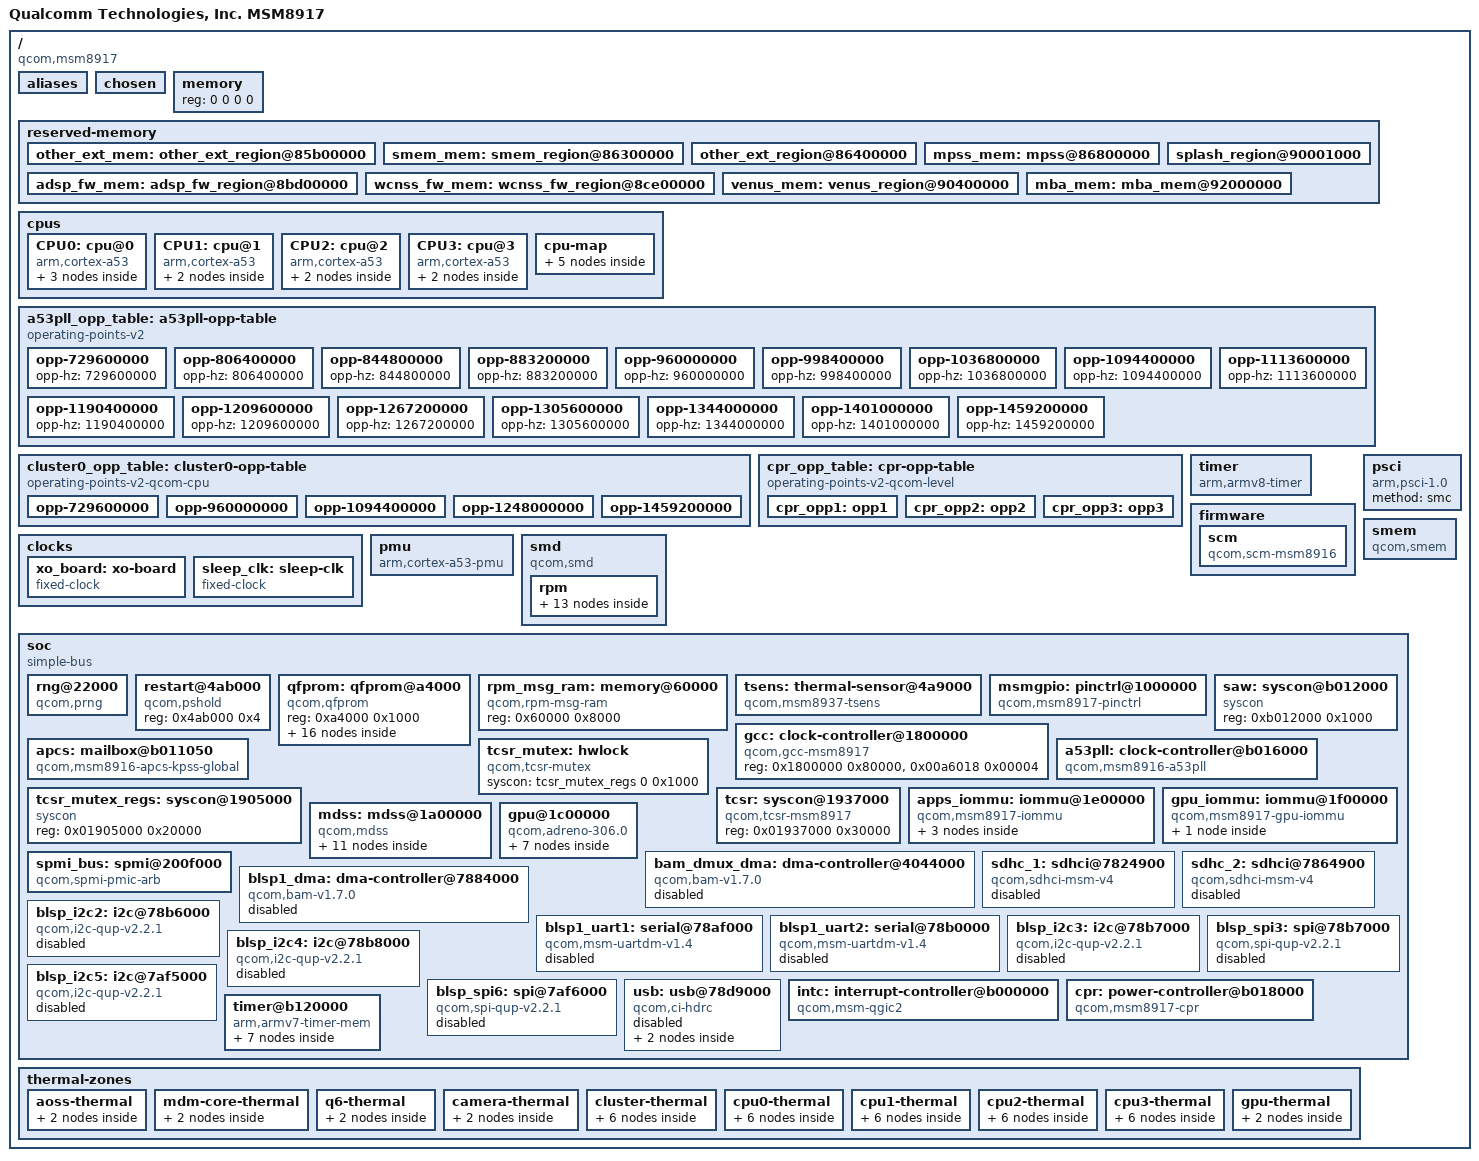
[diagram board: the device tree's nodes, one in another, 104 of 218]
// SPDX-License-Identifier: GPL-2.0-only

#include <dt-bindings/clock/qcom,gcc-msm8937.h>
#include <dt-bindings/clock/qcom,rpmcc.h>
#include <dt-bindings/interrupt-controller/arm-gic.h>
#include <dt-bindings/power/qcom-rpmpd.h>
#include <dt-bindings/thermal/thermal.h>

/ {
	model = "Qualcomm Technologies, Inc. MSM8917";
	compatible = "qcom,msm8917";
	qcom,msm-id = <303 0x0>, <308 0x0>, <309 0x0>;
	interrupt-parent = <&intc>;
	#address-cells = <2>;
	#size-cells = <2>;

	aliases {
		mmc0 = &sdhc_1; /* SDC1 eMMC slot */
		mmc1 = &sdhc_2; /* SDC2 SD card slot */
	};

	chosen { };

	memory {
		device_type = "memory";
		/* We expect the bootloader to fill in the reg */
		reg = <0 0 0 0>;
	};

	reserved-memory {
		#address-cells = <2>;
		#size-cells = <2>;
		ranges;

		other_ext_mem: other_ext_region@85b00000 {
			reg = <0x0 0x85b00000 0x0 0xd00000>;
			no-map;
		};

		smem_mem: smem_region@86300000 {
			reg = <0x0 0x86300000 0x0 0x100000>;
			no-map;
		};

		other_ext_region@86400000 {
			reg = <0x0 0x86400000 0x0 0x400000>;
			no-map;
		};

		mpss_mem: mpss@86800000 {
			reg = <0x0 0x86800000 0x0 0x5500000>;
			no-map;
		};

		adsp_fw_mem: adsp_fw_region@8bd00000 {
			reg = <0x0 0x8bd00000 0x0 0x1100000>;
			no-map;
		};

		wcnss_fw_mem: wcnss_fw_region@8ce00000 {
			reg = <0x0 0x8ce00000 0x0 0x700000>;
			no-map;
		};

		splash_region@90001000 {
			reg = <0x0 0x90000000 0x0 0x1400000>;
			no-map;
		};

		venus_mem: venus_region@90400000 {
			reg = <0x0 0x91400000 0x0 0x700000>;
			no-map;
		};

		mba_mem: mba_mem@92000000 {
			reg = <0x0 0x92000000 0x0 0x100000>;
			no-map;
		};
	};

	cpus {
		#address-cells = <1>;
		#size-cells = <0>;
		CPU0: cpu@0 {
			device_type = "cpu";
			compatible = "arm,cortex-a53";
			capacity-dmips-mhz = <1024>;
			reg = <0x100>;
			next-level-cache = <&L2_0>;
			enable-method = "psci";
			clocks = <&apcs>;
			#cooling-cells = <2>;
			operating-points-v2 = <&cluster0_opp_table>;
			power-domains = <&cpr>;
			power-domain-names = "cpr";
			l1-icache { compatible = "cache"; };
			l1-dcache { compatible = "cache"; };
			L2_0: l2-cache {
				compatible = "cache";
				cache-level = <2>;
			};
		};

		CPU1: cpu@1 {
			device_type = "cpu";
			compatible = "arm,cortex-a53";
			capacity-dmips-mhz = <1024>;
			reg = <0x101>;
			next-level-cache = <&L2_0>;
			enable-method = "psci";
			clocks = <&apcs>;
			#cooling-cells = <2>;
			operating-points-v2 = <&cluster0_opp_table>;
			power-domains = <&cpr>;
			power-domain-names = "cpr";
			l1-icache { compatible = "cache"; };
			l1-dcache { compatible = "cache"; };
		};

		CPU2: cpu@2 {
			device_type = "cpu";
			compatible = "arm,cortex-a53";
			capacity-dmips-mhz = <1024>;
			reg = <0x102>;
			next-level-cache = <&L2_0>;
			enable-method = "psci";
			clocks = <&apcs>;
			#cooling-cells = <2>;
			operating-points-v2 = <&cluster0_opp_table>;
			power-domains = <&cpr>;
			power-domain-names = "cpr";
			l1-icache { compatible = "cache"; };
			l1-dcache { compatible = "cache"; };
		};

		CPU3: cpu@3 {
			device_type = "cpu";
			compatible = "arm,cortex-a53";
			capacity-dmips-mhz = <1024>;
			reg = <0x103>;
			next-level-cache = <&L2_0>;
			enable-method = "psci";
			clocks = <&apcs>;
			#cooling-cells = <2>;
			operating-points-v2 = <&cluster0_opp_table>;
			power-domains = <&cpr>;
			power-domain-names = "cpr";
			l1-icache { compatible = "cache"; };
			l1-dcache { compatible = "cache"; };
		};

		cpu-map {
			cluster0 {
				core0 {
					cpu = <&CPU0>;
				};
				core1 {
					cpu = <&CPU1>;
				};
				core2 {
					cpu = <&CPU2>;
				};
				core3 {
					cpu = <&CPU3>;
				};
			};
		};
	};

	a53pll_opp_table: a53pll-opp-table {
		compatible = "operating-points-v2";
		opp-729600000 { opp-hz = /bits/ 64 <729600000>; };
		opp-806400000 { opp-hz = /bits/ 64 <806400000>; };
		opp-844800000 { opp-hz = /bits/ 64 <844800000>; };
		opp-883200000 { opp-hz = /bits/ 64 <883200000>; };
		opp-960000000 { opp-hz = /bits/ 64 <960000000>; };
		opp-998400000 { opp-hz = /bits/ 64 <998400000>; };
		opp-1036800000 { opp-hz = /bits/ 64 <1036800000>; };
		opp-1094400000 { opp-hz = /bits/ 64 <1094400000>; };
		opp-1113600000 { opp-hz = /bits/ 64 <1113600000>; };
		opp-1190400000 { opp-hz = /bits/ 64 <1190400000>; };
		opp-1209600000 { opp-hz = /bits/ 64 <1209600000>; };
		opp-1267200000 { opp-hz = /bits/ 64 <1267200000>; };
		opp-1305600000 { opp-hz = /bits/ 64 <1305600000>; };
		opp-1344000000 { opp-hz = /bits/ 64 <1344000000>; };
		opp-1401000000 { opp-hz = /bits/ 64 <1401000000>; };
		opp-1459200000 { opp-hz = /bits/ 64 <1459200000>; };
	};

	cluster0_opp_table: cluster0-opp-table {
		compatible = "operating-points-v2-qcom-cpu",
			     	 "operating-points-v2-kryo-cpu";
		nvmem-cells = <&cpr_efuse_speedbin>;
		opp-shared;
		opp-729600000 {
			opp-hz = /bits/ 64 <729600000>;
			required-opps = <&cpr_opp1>;
			opp-suspend;
		};
		opp-960000000 {
			opp-hz = /bits/ 64 <960000000>;
			required-opps = <&cpr_opp1>;
		};
		opp-1094400000 {
			opp-hz = /bits/ 64 <1094400000>;
			required-opps = <&cpr_opp2>;
		};
		opp-1248000000 {
			opp-hz = /bits/ 64 <1248000000>;
			required-opps = <&cpr_opp3>;
		};
		opp-1459200000 {
			opp-hz = /bits/ 64 <1459200000>;
			required-opps = <&cpr_opp3>;
		};
	};

	cpr_opp_table: cpr-opp-table {
		compatible = "operating-points-v2-qcom-level";
		cpr_opp1: opp1 {
			opp-level = <1>;
			qcom,opp-fuse-level = <1>;
		};
		cpr_opp2: opp2 {
			opp-level = <2>;
			qcom,opp-fuse-level = <2>;
		};
		cpr_opp3: opp3 {
			opp-level = <3>;
			qcom,opp-fuse-level = <3>;
		};
	};

	timer {
		compatible = "arm,armv8-timer";
		interrupts = <GIC_PPI 2 (GIC_CPU_MASK_SIMPLE(4) | IRQ_TYPE_LEVEL_LOW)>,
			     <GIC_PPI 3 (GIC_CPU_MASK_SIMPLE(4) | IRQ_TYPE_LEVEL_LOW)>,
			     <GIC_PPI 4 (GIC_CPU_MASK_SIMPLE(4) | IRQ_TYPE_LEVEL_LOW)>,
			     <GIC_PPI 1 (GIC_CPU_MASK_SIMPLE(4) | IRQ_TYPE_LEVEL_LOW)>;
		clock-frequency = <19200000>;
	};

	clocks {
		xo_board: xo-board {
			compatible = "fixed-clock";
			#clock-cells = <0>;
			clock-frequency = <19200000>;
			clock-output-names = "xo";
		};

		sleep_clk: sleep-clk {
			compatible = "fixed-clock";
			#clock-cells = <0>;
			clock-frequency = <32768>;
			clock-output-names = "sleep_clk";
		};
	};
    
	firmware {
		scm: scm {
			compatible = "qcom,scm-msm8916", "qcom,scm";
			clocks = <&gcc GCC_CRYPTO_CLK>,
				 <&gcc GCC_CRYPTO_AXI_CLK>,
				 <&gcc GCC_CRYPTO_AHB_CLK>;
			clock-names = "core", "bus", "iface";
			#reset-cells = <1>;
		};
	};

	pmu {
		compatible = "arm,cortex-a53-pmu";
		interrupts = <GIC_PPI 7 (GIC_CPU_MASK_SIMPLE(4) | IRQ_TYPE_LEVEL_HIGH)>;
	};

	psci {
		compatible = "arm,psci-1.0";
		method = "smc";
	};

	smd {
		compatible = "qcom,smd";

		rpm {
			interrupts = <GIC_SPI 168 IRQ_TYPE_EDGE_RISING>;
			qcom,ipc = <&apcs 8 0>;
			qcom,smd-edge = <15>;

			rpm_requests: rpm-requests {
				compatible = "qcom,rpm-msm8917";
				qcom,smd-channels = "rpm_requests";
				qcom,smd-force-open;

				rpmcc: clock-controller {
					compatible = "qcom,rpmcc-msm8917";
					#clock-cells = <1>;
				};

				rpmpd: power-controller {
					compatible = "qcom,msm8937-rpmpd";
					#power-domain-cells = <1>;
					operating-points-v2 = <&rpmpd_opp_table>;

					clocks = <&xo_board>;
					clock-names = "ref";
					rpmpd_opp_table: opp-table {
						compatible = "operating-points-v2";

						rpmpd_opp_ret: opp1 {
							opp-level = <16>;
						};

						rpmpd_opp_ret_plus: opp2 {
							opp-level = <32>;
						};

						rpmpd_opp_min_svs: opp3 {
							opp-level = <48>;
						};

						rpmpd_opp_low_svs: opp4 {
							opp-level = <64>;
						};

						rpmpd_opp_svs: opp5 {
							opp-level = <128>;
						};

						rpmpd_opp_svs_plus: opp6 {
							opp-level = <192>;
						};

						rpmpd_opp_nom: opp7 {
							opp-level = <256>;
						};

						rpmpd_opp_nom_plus: opp8 {
							opp-level = <320>;
						};

						rpmpd_opp_turbo: opp9 {
							opp-level = <384>;
						};
					};	
				};
			};
		};
	};

	smem {
		compatible = "qcom,smem";
		memory-region = <&smem_mem>;
		qcom,rpm-msg-ram = <&rpm_msg_ram>;
		hwlocks = <&tcsr_mutex 3>;
	};

	soc: soc {
		#address-cells = <1>;
		#size-cells = <1>;
		ranges = <0 0 0 0xffffffff>;
		compatible = "simple-bus";

		rng@22000 {
			compatible = "qcom,prng";
			reg = <0x00022000 0x200>;
			clocks = <&gcc GCC_PRNG_AHB_CLK>;
			clock-names = "core";
		};

		restart@4ab000 {
			compatible = "qcom,pshold";
			reg = <0x4ab000 0x4>;
		};

		qfprom: qfprom@a4000 {
			compatible = "qcom,qfprom";
			reg = <0xa4000 0x1000>;
			#address-cells = <1>;
			#size-cells = <1>;
			tsens_caldata: caldata@d0 {
				reg = <0x1d8 0x14>;
			};
			cpr_efuse_speedbin: speedbin@12c {
				reg = <0x12c 0x4>;
				bits = <2 3>;
			};
			cpr_efuse_init_voltage1: ivoltage1@21c {
				reg = <0x21c 0x4>;
				bits = <4 6>;
			};
			cpr_efuse_init_voltage2: ivoltage2@21a {
				reg = <0x21a 0x4>;
				bits = <2 6>;
			};
			cpr_efuse_init_voltage3: ivoltage3@218 {
				reg = <0x218 0x4>;
				bits = <0 6>;
			};
			cpr_efuse_quot_offset1: qoffset1@23b {
				reg = <0x23b 0x4>;
				bits = <2 6>;
			};
			cpr_efuse_quot_offset2: qoffset2@23a {
				reg = <0x23a 0x4>;
				bits = <4 6>;
			};
			cpr_efuse_quot_offset3: qoffset3@236 {
				reg = <0x236 0x4>;
				bits = <6 7>;
			};
			cpr_efuse_quot1: quot1@21d {
				reg = <0x21d 0x4>;
				bits = <2 12>;
			};
			cpr_efuse_quot2: quot2@21b {
				reg = <0x21b 0x4>;
				bits = <0 12>;
			};
			cpr_efuse_quot3: quot3@218 {
				reg = <0x218 0x4>;
				bits = <2 12>;
			};
			cpr_efuse_ring1: ring1@21f {
				reg = <0x21f 0x4>;
				bits = <4 3>;
			};
			cpr_efuse_ring2: ring2@21f {
				reg = <0x21f 0x4>;
				bits = <1 3>;
			};
			cpr_efuse_ring3: ring3@21e {
				reg = <0x21e 0x4>;
				bits = <6 3>;
			};
			cpr_efuse_revision: revision@22c {
				reg = <0x22c 0x4>;
				bits = <7 3>;
			};
			cpr_pvs_revision: revision@12d {
				reg = <0x12d 0x4>;
				bits = <0 3>;
			};
		};

		rpm_msg_ram: memory@60000 {
			compatible = "qcom,rpm-msg-ram";
			reg = <0x60000 0x8000>;
		};

		tsens: thermal-sensor@4a9000 {
			compatible = "qcom,msm8937-tsens", "qcom,tsens-v1";
			reg = <0x004a9000 0x1000>,
			      <0x004a8000 0x1000>;
			nvmem-cells = <&tsens_caldata>;
			nvmem-cell-names = "calib";
			#qcom,sensors = <10>;
			interrupts = <GIC_SPI 184 IRQ_TYPE_LEVEL_HIGH>;
			interrupt-names = "uplow";
			#thermal-sensor-cells = <1>;
		};

		msmgpio: pinctrl@1000000 {
			compatible = "qcom,msm8917-pinctrl";
			reg = <0x01000000 0x300000>;
			interrupts = <GIC_SPI 208 IRQ_TYPE_LEVEL_HIGH>;
			gpio-controller;
			gpio-ranges = <&msmgpio 0 0 134>;
			gpio-reserved-ranges = <0 4>, <20 4>;
			#gpio-cells = <2>;
			interrupt-controller;
			#interrupt-cells = <2>;
		};

		gcc: clock-controller@1800000 {
			compatible = "qcom,gcc-msm8917", "syscon";
			reg = <0x1800000 0x80000>,
			 <0x00a6018 0x00004>;
			reg-names = "cc_base", "gpu-bin";
			#clock-cells = <1>;
			#reset-cells = <1>;
			#power-domain-cells = <1>;
		};

		saw: syscon@b012000 {
			compatible = "syscon";
			reg = <0xb012000 0x1000>;
		};

		a53pll: clock-controller@b016000 {
			compatible = "qcom,msm8916-a53pll";
			reg = <0xb016000 0x34>;
			#clock-cells = <0>;
			clocks = <&xo_board>;
			clock-names = "xo";
			operating-points-v2 = <&a53pll_opp_table>;
		};

		apcs: mailbox@b011050 {
			compatible = "qcom,msm8916-apcs-kpss-global", "syscon";
			reg = <0xb011000 0x1000>;
			#mbox-cells = <1>;
			clocks = <&a53pll>, <&gcc GPLL0_EARLY>;
			clock-names = "pll", "aux";
			#clock-cells = <0>;
		};

		tcsr_mutex: hwlock {
			compatible = "qcom,tcsr-mutex";
			syscon = <&tcsr_mutex_regs 0 0x1000>;
			#hwlock-cells = <1>;
		};

		tcsr_mutex_regs: syscon@1905000 {
			compatible = "syscon";
			reg = <0x01905000 0x20000>;
		};

		tcsr: syscon@1937000 {
			compatible = "qcom,tcsr-msm8917", "syscon";
			reg = <0x01937000 0x30000>;
		};

		apps_iommu: iommu@1e00000 {
			#address-cells = <1>;
			#size-cells = <1>;
			#iommu-cells = <1>;
			compatible = "qcom,msm8917-iommu", "qcom,msm-iommu-v1";
			ranges  = <0 0x1e20000 0x20000>;
			clocks = <&gcc GCC_SMMU_CFG_CLK>,
				 <&gcc GCC_APSS_TCU_CLK>;
			clock-names = "iface", "bus";
			qcom,iommu-secure-id = <17>;

			iommu-ctx@14000 { // vfe
				compatible = "qcom,msm-iommu-v1-ns";
				reg = <0x14000 0x1000>;
				interrupts = <GIC_SPI 111 IRQ_TYPE_LEVEL_HIGH>;
			};

			iommu-ctx@15000 { // mdp_0
				compatible = "qcom,msm-iommu-v1-ns";
				reg = <0x15000 0x1000>;
				interrupts = <GIC_SPI 112 IRQ_TYPE_LEVEL_HIGH>;
			};

			iommu-ctx@16000 { // venus_ns
				compatible = "qcom,msm-iommu-v1-ns";
				reg = <0x16000 0x1000>;
				interrupts = <GIC_SPI 113 IRQ_TYPE_LEVEL_HIGH>;
			};
		};

		gpu_iommu: iommu@1f00000 {
			#address-cells = <1>;
			#size-cells = <1>;
			#iommu-cells = <1>;
			compatible = "qcom,msm8917-gpu-iommu", "qcom,msm-iommu-v1";
			ranges  = <0 0x1f08000 0x8000>;
			clocks = <&gcc GCC_SMMU_CFG_CLK>,
				 <&gcc GCC_GFX_TCU_CLK>;
			clock-names = "iface", "bus";
			qcom,iommu-secure-id = <18>;

			iommu-ctx@0000 { // gfx3d_user
				compatible = "qcom,msm-iommu-v1-ns";
				reg = <0x0000 0x1000>;
				interrupts = <GIC_SPI 241 IRQ_TYPE_LEVEL_HIGH>;
			};
		};

		mdss: mdss@1a00000 {
			compatible = "qcom,mdss";
			reg = <0x1a00000 0x1000>,
			      <0x1ab0000 0x1040>;
			reg-names = "mdss_phys", "vbif_phys";

			power-domains = <&gcc MDSS_GDSC>;

			clocks = <&gcc GCC_MDSS_AHB_CLK>,
				 <&gcc GCC_MDSS_AXI_CLK>,
				 <&gcc GCC_MDSS_VSYNC_CLK>;
			clock-names = "iface",
				      "bus",
				      "vsync";

			interrupts = <GIC_SPI 72 IRQ_TYPE_LEVEL_HIGH>;

			interrupt-controller;
			#interrupt-cells = <1>;

			#address-cells = <1>;
			#size-cells = <1>;
			ranges;

			dsi_phy0: dsi-phy@1a94400 {
				compatible = "qcom,dsi-phy-28nm-lp-single-fam-b";
				reg = <0x1a94a00 0xd4>,
				      <0x1a94400 0x280>,
				      <0x1a94b80 0x30>;
				reg-names = "dsi_pll",
					    "dsi_phy",
					    "dsi_phy_regulator";

				#clock-cells = <1>;
				#phy-cells = <0>;

				clocks = <&gcc GCC_MDSS_AHB_CLK>,
					 <&xo_board>;
				clock-names = "iface", "ref";
			};

			dsi0: dsi@1a94000 {
				compatible = "qcom,mdss-dsi-ctrl";
				reg = <0x1a94000 0x300>;
				reg-names = "dsi_ctrl";

				interrupt-parent = <&mdss>;
				interrupts = <4>;

				assigned-clocks = <&gcc BYTE0_CLK_SRC>,
						  <&gcc PCLK0_CLK_SRC>;
				assigned-clock-parents = <&dsi_phy0 0>,
							 <&dsi_phy0 1>;

				clocks = <&gcc GCC_MDSS_MDP_CLK>,
					 <&gcc GCC_MDSS_AHB_CLK>,
					 <&gcc GCC_MDSS_AXI_CLK>,
					 <&gcc GCC_MDSS_BYTE0_CLK>,
					 <&gcc GCC_MDSS_PCLK0_CLK>,
					 <&gcc GCC_MDSS_ESC0_CLK>;
				clock-names = "mdp_core",
					      "iface",
					      "bus",
					      "byte",
					      "pixel",
					      "core";
				phys = <&dsi_phy0>;
				phy-names = "dsi-phy";

				#address-cells = <1>;
				#size-cells = <0>;

				ports {
					#address-cells = <1>;
					#size-cells = <0>;

					port@0 {
						reg = <0>;
						dsi0_in: endpoint {
							remote-endpoint = <&mdp5_intf1_out>;
						};
					};

					port@1 {
						reg = <1>;
						dsi0_out: endpoint {
						};
					};
				};
			};

			mdp: mdp@1a01000 {
				compatible = "qcom,mdp5";
				reg = <0x01a01000 0x89000>;
				reg-names = "mdp_phys";

				interrupt-parent = <&mdss>;
				interrupts = <0>;

				clocks = <&gcc GCC_MDSS_AHB_CLK>,
					 <&gcc GCC_MDSS_AXI_CLK>,
					 <&gcc GCC_MDSS_MDP_CLK>,
					 <&gcc GCC_MDSS_VSYNC_CLK>;
				clock-names = "iface",
					      "bus",
					      "core",
					      "vsync";

				iommus = <&apps_iommu 0x15>;
				iommu-defer-attach;

				ports {
					#address-cells = <1>;
					#size-cells = <0>;

					port@0 {
						reg = <0>;
						mdp5_intf1_out: endpoint {
							remote-endpoint = <&dsi0_in>;
						};
					};
				};
			};
		};

		gpu@1c00000 {
			compatible = "qcom,adreno-306.0", "qcom,adreno";
			reg = <0x1c00000 0x20000>;
			reg-names = "kgsl_3d0_reg_memory";
			interrupts = <GIC_SPI 33 IRQ_TYPE_LEVEL_HIGH>;
			interrupt-names = "kgsl_3d0_irq";
			clocks = <&gcc GCC_OXILI_GFX3D_CLK>,
				 <&gcc GCC_OXILI_AHB_CLK>,
				 <&gcc GCC_BIMC_GFX_CLK>,
				 <&gcc GCC_BIMC_GPU_CLK>,
				 <&gcc GCC_GTCU_AHB_CLK>,
				 <&gcc GCC_GFX_TCU_CLK>,
				 <&gcc GCC_GFX_TBU_CLK>;
				 //<&rpmcc RPM_SMD_BIMC_GPU_CLK>;

			clock-names = "core", 
						  "iface", 
						  "mem_iface",
						  "alt_mem_iface", 
						  "gtcu_iface",
						  "gtcu", 
						  "gtbu";
						 // "bimc_gpu";
			power-domains = <&gcc OXILI_GX_GDSC>;
			operating-points-v2 = <&gpu_opp_table>;
			#cooling-cells = <2>;
			iommus = <&gpu_iommu 0>;

			gpu_opp_table: opp-table {
				compatible  ="operating-points-v2";
				opp-598000000 {
					opp-hz = /bits/ 64 <598000000>;
				};
				opp-523200000 {
					opp-hz = /bits/ 64 <523200000>;
				};
				opp-484800000 {
					opp-hz = /bits/ 64 <484800000>;
				};
				opp-400000000 {
					opp-hz = /bits/ 64 <400000000>;
				};
				opp-270000000 {
					opp-hz = /bits/ 64 <270000000>;
				};
				opp-19200000 {
					opp-hz = /bits/ 64 <19200000>;
				};
			};
		};

		spmi_bus: spmi@200f000 {
			compatible = "qcom,spmi-pmic-arb";
			reg = <0x0200f000 0x001000>,
			      <0x02400000 0x800000>,
			      <0x02c00000 0x800000>,
			      <0x03800000 0x200000>,
			      <0x0200a000 0x002100>;
			reg-names = "core", "chnls", "obsrvr", "intr", "cnfg";
			interrupt-names = "periph_irq";
			interrupts = <GIC_SPI 190 IRQ_TYPE_LEVEL_HIGH>;
			qcom,ee = <0>;
			qcom,channel = <0>;
			#address-cells = <2>;
			#size-cells = <0>;
			interrupt-controller;
			#interrupt-cells = <4>;
		};

		bam_dmux_dma: dma-controller@4044000 {
			compatible = "qcom,bam-v1.7.0";
			reg = <0x04044000 0x19000>;
			interrupts = <GIC_SPI 29 IRQ_TYPE_LEVEL_HIGH>;
			#dma-cells = <1>;
			qcom,ee = <0>;

			num-channels = <6>;
			qcom,num-ees = <1>;
			qcom,remote-power-collapse;

			status = "disabled";
		};

		sdhc_1: sdhci@7824900 {
			compatible = "qcom,sdhci-msm-v4";
			reg = <0x7824900 0x500>, <0x7824000 0x800>;
			reg-names = "hc_mem", "core_mem";

			interrupts = <GIC_SPI 123 IRQ_TYPE_LEVEL_HIGH>,
				     <GIC_SPI 138 IRQ_TYPE_LEVEL_HIGH>;
			interrupt-names = "hc_irq", "pwr_irq";
			clocks = <&gcc GCC_SDCC1_APPS_CLK>,
				 <&gcc GCC_SDCC1_AHB_CLK>,
				 <&xo_board>;
			clock-names = "core", "iface", "xo";
			mmc-hs200-1_8v;
			mmc-hs400-1_8v;
			mmc-ddr-1_8v;
			bus-width = <8>;
			non-removable;
			status = "disabled";
		};

		sdhc_2: sdhci@7864900 {
			compatible = "qcom,sdhci-msm-v4";
			reg = <0x7864900 0x500>, <0x7864000 0x800>;
			reg-names = "hc_mem", "core_mem";

			interrupts = <GIC_SPI 125 IRQ_TYPE_LEVEL_HIGH>,
				     <GIC_SPI 221 IRQ_TYPE_LEVEL_HIGH>;
			interrupt-names = "hc_irq", "pwr_irq";
			clocks = <&gcc GCC_SDCC2_APPS_CLK>,
				 <&gcc GCC_SDCC2_AHB_CLK>,
				 <&xo_board>;
			clock-names = "core", "iface", "xo";
			bus-width = <4>;
			status = "disabled";
		};

		blsp1_dma: dma-controller@7884000 {
			compatible = "qcom,bam-v1.7.0";
			reg = <0x07884000 0x1f000>;
			interrupts = <GIC_SPI 238 IRQ_TYPE_LEVEL_HIGH>;
			clocks = <&gcc GCC_BLSP1_AHB_CLK>;
			clock-names = "bam_clk";
			#dma-cells = <1>;
			qcom,ee = <0>;
			status = "disabled";
		};

		blsp1_uart1: serial@78af000 {
			compatible = "qcom,msm-uartdm-v1.4", "qcom,msm-uartdm";
			reg = <0x078af000 0x200>;
			interrupts = <GIC_SPI 107 IRQ_TYPE_LEVEL_HIGH>;
			clocks = <&gcc GCC_BLSP1_UART1_APPS_CLK>,
				<&gcc GCC_BLSP1_AHB_CLK>;
			clock-names = "core", "iface";
			dmas = <&blsp1_dma 1>, <&blsp1_dma 0>;
			dma-names = "rx", "tx";
			pinctrl-names = "default", "sleep";
			pinctrl-0 = <&blsp1_uart1_active>;
			pinctrl-1 = <&blsp1_uart1_sleep>;
			status = "disabled";
		};

		blsp1_uart2: serial@78b0000 {
			compatible = "qcom,msm-uartdm-v1.4", "qcom,msm-uartdm";
			reg = <0x078b0000 0x200>;
			interrupts = <GIC_SPI 108 IRQ_TYPE_LEVEL_HIGH>;
			clocks = <&gcc GCC_BLSP1_UART2_APPS_CLK>,
				<&gcc GCC_BLSP1_AHB_CLK>;
			clock-names = "core", "iface";
			dmas = <&blsp1_dma 3>, <&blsp1_dma 2>;
			dma-names = "rx", "tx";
			pinctrl-names = "default", "sleep";
			pinctrl-0 = <&blsp1_uart1_active>;
			pinctrl-1 = <&blsp1_uart1_sleep>;
			status = "disabled";
		};

		blsp_i2c2: i2c@78b6000 {
			compatible = "qcom,i2c-qup-v2.2.1";
			reg = <0x078b6000 0x600>;
			interrupts = <GIC_SPI 96 IRQ_TYPE_LEVEL_HIGH>;
			clocks = <&gcc GCC_BLSP1_AHB_CLK>,
				<&gcc GCC_BLSP1_QUP2_I2C_APPS_CLK>;
			clock-names = "iface", "core";
			pinctrl-names = "default", "sleep";
			pinctrl-0 = <&i2c_2_default>;
			pinctrl-1 = <&i2c_2_sleep>;
			#address-cells = <1>;
			#size-cells = <0>;
			status = "disabled";
		};

		blsp_i2c3: i2c@78b7000 {
			compatible = "qcom,i2c-qup-v2.2.1";
			reg = <0x078b7000 0x600>;
			interrupts = <GIC_SPI 97 IRQ_TYPE_LEVEL_HIGH>;
			clocks = <&gcc GCC_BLSP1_AHB_CLK>,
				 <&gcc GCC_BLSP1_QUP3_I2C_APPS_CLK>;
			clock-names = "iface", "core";
			pinctrl-names = "default", "sleep";
			pinctrl-0 = <&i2c_3_default>;
			pinctrl-1 = <&i2c_3_sleep>;
			#address-cells = <1>;
			#size-cells = <0>;
			status = "disabled";
		};

		blsp_spi3: spi@78b7000 {
			compatible = "qcom,spi-qup-v2.2.1";
			reg = <0x078b7000 0x600>;
			interrupts = <GIC_SPI 97 IRQ_TYPE_LEVEL_HIGH>;
			clocks = <&gcc GCC_BLSP1_AHB_CLK>,
				<&gcc GCC_BLSP1_QUP3_I2C_APPS_CLK>;
			clock-names = "core", "iface";
			pinctrl-names = "default", "sleep";
			pinctrl-0 = <&spi3_default>;
			pinctrl-1 = <&spi3_sleep>;
			#address-cells = <1>;
			#size-cells = <0>;
			status = "disabled";
		};

		blsp_i2c4: i2c@78b8000 {
			compatible = "qcom,i2c-qup-v2.2.1";
			reg = <0x078b8000 0x500>;
			interrupts = <GIC_SPI 98 IRQ_TYPE_LEVEL_HIGH>;
			clocks = <&gcc GCC_BLSP1_AHB_CLK>,
				<&gcc GCC_BLSP1_QUP4_I2C_APPS_CLK>;
			clock-names = "iface", "core";
			pinctrl-names = "default", "sleep";
			pinctrl-0 = <&i2c_4_default>;
			pinctrl-1 = <&i2c_4_sleep>;
			#address-cells = <1>;
			#size-cells = <0>;
			status = "disabled";
		};

		blsp_i2c5: i2c@7af5000 {
			compatible = "qcom,i2c-qup-v2.2.1";
			reg = <0x7af5000 0x600>;
			interrupts = <GIC_SPI 299 IRQ_TYPE_LEVEL_HIGH>;
			clocks = <&gcc GCC_BLSP2_AHB_CLK>,
				<&gcc GCC_BLSP2_QUP1_I2C_APPS_CLK>;
			clock-names = "iface", "core";
			pinctrl-names = "default", "sleep";
			pinctrl-0 = <&i2c_5_default>;
			pinctrl-1 = <&i2c_5_sleep>;
			#address-cells = <1>;
			#size-cells = <0>;
			status = "disabled";
		};

		blsp_spi6: spi@7af6000 {
			compatible = "qcom,spi-qup-v2.2.1";
			reg = <0x7af6000 0x600>;
			interrupts = <GIC_SPI 300 IRQ_TYPE_LEVEL_HIGH>;
			clocks = <&gcc GCC_BLSP2_AHB_CLK>,
				<&gcc GCC_BLSP2_QUP2_SPI_APPS_CLK>;
			clock-names = "iface", "core";
			pinctrl-names = "default", "sleep";
			pinctrl-0 = <&spi6_default>;
			pinctrl-1 = <&spi6_sleep>;
			#address-cells = <1>;
			#size-cells = <0>;
			status = "disabled";
		};

		usb: usb@78d9000 {
			compatible = "qcom,ci-hdrc";
			reg = <0x078d9000 0x200>,
			      <0x078d9200 0x200>;
			interrupts = <GIC_SPI 134 IRQ_TYPE_LEVEL_HIGH>,
				     <GIC_SPI 140 IRQ_TYPE_LEVEL_HIGH>;
			clocks = <&gcc GCC_USB_HS_AHB_CLK>,
				 <&gcc GCC_USB_HS_SYSTEM_CLK>;
			clock-names = "iface", "core";
			assigned-clocks = <&gcc GCC_USB_HS_SYSTEM_CLK>;
			assigned-clock-rates = <80000000>;
			resets = <&gcc GCC_USB_HS_BCR>;
			reset-names = "core";
			phy_type = "ulpi";
			dr_mode = "otg";
			hnp-disable;
			srp-disable;
			adp-disable;
			ahb-burst-config = <0>;
			phy-names = "usb-phy";
			phys = <&usb_hs_phy>;
			status = "disabled";
			#reset-cells = <1>;

			ulpi {
				usb_hs_phy: phy {
					compatible = "qcom,usb-hs-phy-msm8916",
						     "qcom,usb-hs-phy";
					#phy-cells = <0>;
					clocks = <&xo_board>, <&gcc GCC_USB2A_PHY_SLEEP_CLK>;
					clock-names = "ref", "sleep";
					resets = <&gcc GCC_QUSB2_PHY_BCR>, <&usb 0>;
					reset-names = "phy", "por";
					qcom,init-seq = /bits/ 8 <0x0 0x44
						0x1 0x6b 0x2 0x24 0x3 0x13>;
				};
			};
		};

		intc: interrupt-controller@b000000 {
			compatible = "qcom,msm-qgic2";
			interrupt-controller;
			#interrupt-cells = <3>;
			reg = <0x0b000000 0x1000>,
			      <0x0b002000 0x1000>;
		};

		cpr: power-controller@b018000 {
			compatible = "qcom,msm8917-cpr", "qcom,cpr";
			reg = <0x0b018000 0x1000>;
			interrupts = <GIC_SPI 15 IRQ_TYPE_EDGE_RISING>;
			clocks = <&xo_board>;
			clock-names = "ref";
			#power-domain-cells = <0>;
			operating-points-v2 = <&cpr_opp_table>;
			acc-syscon = <&tcsr>;

			nvmem-cells = <&cpr_efuse_init_voltage1>,
				<&cpr_efuse_init_voltage2>,
				<&cpr_efuse_init_voltage3>,
				<&cpr_efuse_quot_offset1>,
				<&cpr_efuse_quot_offset2>,
				<&cpr_efuse_quot_offset3>,
				<&cpr_efuse_quot1>,
				<&cpr_efuse_quot2>,
				<&cpr_efuse_quot3>,
				<&cpr_efuse_ring1>,
				<&cpr_efuse_ring2>,
				<&cpr_efuse_ring3>,
				<&cpr_efuse_revision>;
			nvmem-cell-names =  "cpr_init_voltage1",
				"cpr_init_voltage2",
				"cpr_init_voltage3",
				"cpr_quotient_offset1",
				"cpr_quotient_offset2",
				"cpr_quotient_offset3",
				"cpr_quotient1",
				"cpr_quotient2",
				"cpr_quotient3",
				"cpr_ring_osc1",
				"cpr_ring_osc2",
				"cpr_ring_osc3",
				"cpr_fuse_revision";
		};

		timer@b120000 {
			#address-cells = <1>;
			#size-cells = <1>;
			ranges;
			compatible = "arm,armv7-timer-mem";
			reg = <0x0b120000 0x1000>;
			clock-frequency = <19200000>;

			frame@b121000 {
				frame-number = <0>;
				interrupts = <GIC_SPI 8 IRQ_TYPE_LEVEL_HIGH>,
					     <GIC_SPI 7 IRQ_TYPE_LEVEL_HIGH>;
				reg = <0x0b121000 0x1000>,
				      <0x0b122000 0x1000>;
			};

			frame@b123000 {
				frame-number = <1>;
				interrupts = <GIC_SPI 9 IRQ_TYPE_LEVEL_HIGH>;
				reg = <0x0b123000 0x1000>;
				status = "disabled";
			};

			frame@b124000 {
				frame-number = <2>;
				interrupts = <GIC_SPI 10 IRQ_TYPE_LEVEL_HIGH>;
				reg = <0x0b124000 0x1000>;
				status = "disabled";
			};

			frame@b125000 {
				frame-number = <3>;
				interrupts = <GIC_SPI 11 IRQ_TYPE_LEVEL_HIGH>;
				reg = <0x0b125000 0x1000>;
				status = "disabled";
			};

			frame@b126000 {
				frame-number = <4>;
				interrupts = <GIC_SPI 12 IRQ_TYPE_LEVEL_HIGH>;
				reg = <0x0b126000 0x1000>;
				status = "disabled";
			};

			frame@b127000 {
				frame-number = <5>;
				interrupts = <GIC_SPI 13 IRQ_TYPE_LEVEL_HIGH>;
				reg = <0xb127000 0x1000>;
				status = "disabled";
			};

			frame@b128000 {
				frame-number = <6>;
				interrupts = <GIC_SPI 14 IRQ_TYPE_LEVEL_HIGH>;
				reg = <0x0b128000 0x1000>;
				status = "disabled";
			};
		};
	};

	thermal-zones {
		aoss-thermal {
			polling-delay-passive = <250>;
			polling-delay = <1000>;

			thermal-sensors = <&tsens 0>;

			trips {
				aoss_alert0: trip-point0 {
					temperature = <105000>;
					hysteresis = <2000>;
					type = "hot";
				};
			};
		};

		mdm-core-thermal {
			polling-delay-passive = <250>;
			polling-delay = <1000>;

			thermal-sensors = <&tsens 1>;

			trips {
				mdm_core_alert0: trip-point0 {
					temperature = <105000>;
					hysteresis = <2000>;
					type = "hot";
				};
			};
		};

		q6-thermal {
			polling-delay-passive = <250>;
			polling-delay = <1000>;

			thermal-sensors = <&tsens 2>;

			trips {
				q6_alert0: trip-point0 {
					temperature = <105000>;
					hysteresis = <2000>;
					type = "hot";
				};
			};
		};

		camera-thermal {
			polling-delay-passive = <250>;
			polling-delay = <1000>;

			thermal-sensors = <&tsens 3>;

			trips {
				camera_alert0: trip-point0 {
					temperature = <105000>;
					hysteresis = <2000>;
					type = "hot";
				};
			};
		};

		cluster-thermal {
			polling-delay-passive = <250>;
			polling-delay = <1000>;

			thermal-sensors = <&tsens 4>;

			trips {
				cluster_alert0: trip-point0 {
					temperature = <95000>;
					hysteresis = <2000>;
					type = "hot";
				};
				cluster_alert1: trip-point1 {
					temperature = <105000>;
					hysteresis = <2000>;
					type = "passive";
				};
				cluster_crit: cluster_crit {
					temperature = <120000>;
					hysteresis = <2000>;
					type = "critical";
				};
			};
			cooling-maps {
				map0 {
					trip = <&cluster_alert1>;
					cooling-device = <&CPU0 THERMAL_NO_LIMIT THERMAL_NO_LIMIT>,
						       <&CPU1 THERMAL_NO_LIMIT THERMAL_NO_LIMIT>,
						       <&CPU2 THERMAL_NO_LIMIT THERMAL_NO_LIMIT>,
						       <&CPU3 THERMAL_NO_LIMIT THERMAL_NO_LIMIT>;
				};
			};
		};

		cpu0-thermal {
			polling-delay-passive = <250>;
			polling-delay = <1000>;

			thermal-sensors = <&tsens 5>;

			trips {
				cpu0_alert0: trip-point0 {
					temperature = <95000>;
					hysteresis = <2000>;
					type = "hot";
				};
				cpu0_alert1: trip-point1 {
					temperature = <105000>;
					hysteresis = <2000>;
					type = "passive";
				};
				cpu0_crit: cpu_crit {
					temperature = <120000>;
					hysteresis = <2000>;
					type = "critical";
				};
			};
			cooling-maps {
				map0 {
					trip = <&cpu0_alert1>;
					cooling-device = <&CPU0 THERMAL_NO_LIMIT THERMAL_NO_LIMIT>,
						       <&CPU1 THERMAL_NO_LIMIT THERMAL_NO_LIMIT>,
						       <&CPU2 THERMAL_NO_LIMIT THERMAL_NO_LIMIT>,
						       <&CPU3 THERMAL_NO_LIMIT THERMAL_NO_LIMIT>;
				};
			};
		};

		cpu1-thermal {
			polling-delay-passive = <250>;
			polling-delay = <1000>;

			thermal-sensors = <&tsens 6>;

			trips {
				cpu1_alert0: trip-point0 {
					temperature = <95000>;
					hysteresis = <2000>;
					type = "hot";
				};
				cpu1_alert1: trip-point1 {
					temperature = <105000>;
					hysteresis = <2000>;
					type = "passive";
				};
				cpu1_crit: cpu_crit {
					temperature = <120000>;
					hysteresis = <2000>;
					type = "critical";
				};
			};
			cooling-maps {
				map0 {
					trip = <&cpu1_alert1>;
					cooling-device = <&CPU0 THERMAL_NO_LIMIT THERMAL_NO_LIMIT>,
						       <&CPU1 THERMAL_NO_LIMIT THERMAL_NO_LIMIT>,
						       <&CPU2 THERMAL_NO_LIMIT THERMAL_NO_LIMIT>,
						       <&CPU3 THERMAL_NO_LIMIT THERMAL_NO_LIMIT>;
				};
			};
		};

		cpu2-thermal {
			polling-delay-passive = <250>;
			polling-delay = <1000>;

			thermal-sensors = <&tsens 7>;

			trips {
				cpu2_alert0: trip-point0 {
					temperature = <95000>;
					hysteresis = <2000>;
					type = "hot";
				};
				cpu2_alert1: trip-point1 {
					temperature = <105000>;
					hysteresis = <2000>;
					type = "passive";
				};
				cpu2_crit: cpu_crit {
					temperature = <120000>;
					hysteresis = <2000>;
					type = "critical";
				};
			};
			cooling-maps {
				map0 {
					trip = <&cpu2_alert1>;
					cooling-device = <&CPU0 THERMAL_NO_LIMIT THERMAL_NO_LIMIT>,
						       <&CPU1 THERMAL_NO_LIMIT THERMAL_NO_LIMIT>,
						       <&CPU2 THERMAL_NO_LIMIT THERMAL_NO_LIMIT>,
						       <&CPU3 THERMAL_NO_LIMIT THERMAL_NO_LIMIT>;
				};
			};
		};

		cpu3-thermal {
			polling-delay-passive = <250>;
			polling-delay = <1000>;

			thermal-sensors = <&tsens 8>;

			trips {
				cpu3_alert0: trip-point0 {
					temperature = <95000>;
					hysteresis = <2000>;
					type = "hot";
				};
				cpu3_alert1: trip-point1 {
					temperature = <105000>;
					hysteresis = <2000>;
					type = "passive";
				};
				cpu3_crit: cpu_crit {
					temperature = <120000>;
					hysteresis = <2000>;
					type = "critical";
				};
			};
			cooling-maps {
				map0 {
					trip = <&cpu3_alert1>;
					cooling-device = <&CPU0 THERMAL_NO_LIMIT THERMAL_NO_LIMIT>,
						       <&CPU1 THERMAL_NO_LIMIT THERMAL_NO_LIMIT>,
						       <&CPU2 THERMAL_NO_LIMIT THERMAL_NO_LIMIT>,
						       <&CPU3 THERMAL_NO_LIMIT THERMAL_NO_LIMIT>;
				};
			};
		};

		gpu-thermal {
			polling-delay-passive = <250>;
			polling-delay = <1000>;

			thermal-sensors = <&tsens 9>;

			trips {
				gpu_alert0: trip-point0 {
					temperature = <95000>;
					hysteresis = <2000>;
					type = "hot";
				};
			};
		};
	};
};

#include "msm8917-pins.dtsi"
